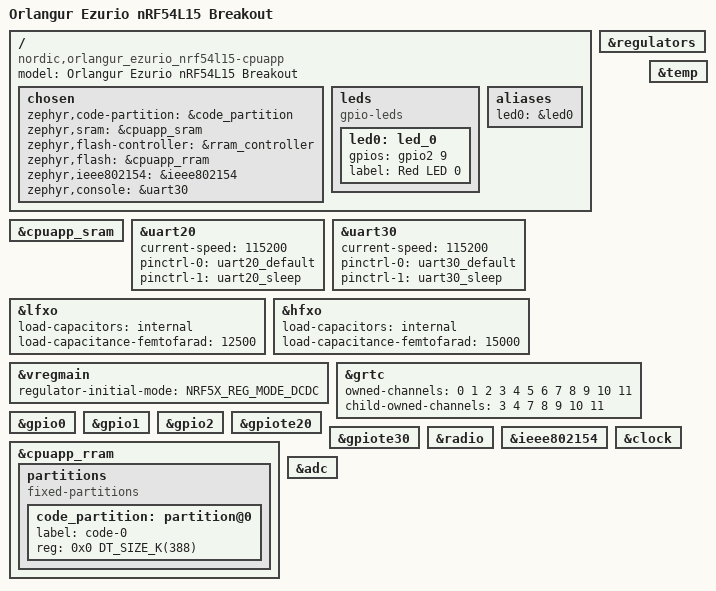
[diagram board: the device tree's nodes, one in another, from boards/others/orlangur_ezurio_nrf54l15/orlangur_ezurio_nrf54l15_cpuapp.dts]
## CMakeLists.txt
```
# SPDX-License-Identifier: Apache-2.0

cmake_minimum_required(VERSION 3.20.0)

find_package(Zephyr REQUIRED HINTS $ENV{ZEPHYR_BASE})
project(nrf54l15_breakout_test)

target_sources(app PRIVATE src/main.cpp)
target_link_libraries(app PRIVATE c stdc++ supc++)
target_compile_options(app PRIVATE -fmacro-backtrace-limit=0)
```

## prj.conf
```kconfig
#
# Copyright (c) 2020 Nordic Semiconductor ASA
#
# SPDX-License-Identifier: LicenseRef-Nordic-5-Clause
#
CONFIG_LIBGCC_RTLIB=y
CONFIG_PICOLIBC=y
CONFIG_CPP=y
CONFIG_STD_CPP2B=y
CONFIG_LLVM_USE_LLD=y
# CONFIG_LTO=y
# CONFIG_ISR_TABLES_LOCAL_DECLARATION=y

CONFIG_UART_INTERRUPT_DRIVEN=y
CONFIG_SERIAL=y
CONFIG_GPIO=y
# CONFIG_PWM=y
# CONFIG_ADC=y

CONFIG_REBOOT=y
CONFIG_RAM_POWER_DOWN_LIBRARY=y
CONFIG_SETTINGS=y
CONFIG_REGULATOR=y

CONFIG_CONSOLE=y
CONFIG_UART_CONSOLE=y

CONFIG_LOG=y
CONFIG_LOG_MAX_LEVEL=4
# CONFIG_LOG_BACKEND_RTT=y
# CONFIG_USE_SEGGER_RTT=y
CONFIG_PRINTK=y
```

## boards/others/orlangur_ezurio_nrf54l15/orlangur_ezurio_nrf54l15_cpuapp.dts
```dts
/*
 * Copyright (c) 2024 Nordic Semiconductor ASA
 *
 * SPDX-License-Identifier: Apache-2.0
 */

/dts-v1/;

#include <nordic/nrf54l15_cpuapp.dtsi>
#include "pinctrl.dtsi"

/ {
	compatible = "nordic,orlangur_ezurio_nrf54l15-cpuapp";
	model = "Orlangur Ezurio nRF54L15 Breakout";

	chosen {
		zephyr,code-partition = &code_partition;
		zephyr,sram = &cpuapp_sram;
		zephyr,flash-controller = &rram_controller;
		zephyr,flash = &cpuapp_rram;
		zephyr,ieee802154 = &ieee802154;
		zephyr,console = &uart30;
	};

	leds {
		compatible = "gpio-leds";
		led0: led_0 {
			gpios = <&gpio2 9 GPIO_ACTIVE_HIGH>;
			label = "Red LED 0";
		};
	};

	aliases {
		led0 = &led0;
	};
};

&cpuapp_sram {
	status = "okay";
};

&uart20 {
	current-speed = <115200>;
	pinctrl-0 = <&uart20_default>;
	pinctrl-1 = <&uart20_sleep>;
	pinctrl-names = "default", "sleep";
};

&uart30 {
	status = "okay";
	current-speed = <115200>;
	pinctrl-0 = <&uart30_default>;
	pinctrl-1 = <&uart30_sleep>;
	pinctrl-names = "default", "sleep";
};

&lfxo {
	load-capacitors = "internal";
	load-capacitance-femtofarad = <12500>;
};

&hfxo {
	load-capacitors = "internal";
	load-capacitance-femtofarad = <15000>;
};

&regulators {
	status = "okay";
};

&vregmain {
	status = "okay";
	regulator-initial-mode = <NRF5X_REG_MODE_DCDC>;
};

&grtc {
	owned-channels = <0 1 2 3 4 5 6 7 8 9 10 11>;
	/* Channels 7-11 reserved for Zero Latency IRQs, 3-4 for FLPR */
	child-owned-channels = <3 4 7 8 9 10 11>;
	status = "okay";
};

&gpio0 {
	status = "okay";
};

&gpio1 {
	status = "okay";
};

&gpio2 {
	status = "okay";
};

&gpiote20 {
	status = "okay";
};

&gpiote30 {
	status = "okay";
};

&radio {
	status = "okay";
};

&ieee802154 {
	status = "okay";
};

&temp {
	status = "okay";
};

&clock {
	status = "okay";
};

&cpuapp_rram {
	status = "okay";
	partitions {
		compatible = "fixed-partitions";
		#address-cells = <1>;
		#size-cells = <1>;
		code_partition: partition@0 {
			label = "code-0";
			reg = <0x0 DT_SIZE_K(388)>;
		};
	};
};

&adc {
	status = "okay";
};
```

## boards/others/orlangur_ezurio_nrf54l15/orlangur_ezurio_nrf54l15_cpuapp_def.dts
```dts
/*
 * Copyright (c) 2024 Nordic Semiconductor ASA
 *
 * SPDX-License-Identifier: Apache-2.0
 */

/dts-v1/;
#include "orlangur_ezurio_nrf54l15_cpuapp.dts"
```

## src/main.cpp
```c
/*
 * Copyright (c) 2023, Meta
 *
 * SPDX-License-Identifier: Apache-2.0
 */

//#include <iostream>
#include <memory>

#include <zephyr/kernel.h>
#include <zephyr/drivers/gpio.h>
#include <zephyr/drivers/uart.h>

/* 1000 msec = 1 sec */
#define SLEEP_TIME_MS   1000

/* The devicetree node identifier for the "led0" alias. */
#define LED0_NODE DT_ALIAS(led0)

#define UART_DEVICE_NODE DT_CHOSEN(zephyr_console)
static const struct device *const uart_dev = DEVICE_DT_GET(UART_DEVICE_NODE);

/*
 * A build error on this line means your board is unsupported.
 * See the sample documentation for information on how to fix this.
 */
static const struct gpio_dt_spec led = GPIO_DT_SPEC_GET(LED0_NODE, gpios);

void print_uart(const char *buf)
{
	while(*buf)
		uart_poll_out(uart_dev, *buf++);
}

int main(void)
{
	int ret;
	bool led_state = true;

	 if (!gpio_is_ready_dt(&led)) {
	 	return 0;
	 }
	 ret = gpio_pin_configure_dt(&led, GPIO_OUTPUT_ACTIVE);
	 if (ret < 0) {
	 	return 0;
	 }

	while (1) {
		 ret = gpio_pin_toggle_dt(&led);
		 if (ret < 0) return 0;

		led_state = !led_state;
		printk("LED: %s\r\n", led_state ? "ON" : "OFF");
		//if (led_state)
		//	print_uart("LED state: ON\r\n");
		//else
		//	print_uart("LED state: OFF\r\n");
		k_msleep(SLEEP_TIME_MS);
	}

	//std::unique_ptr<int> ptr;
	//std::shared_ptr<char> ptr2;
	//std::cout << "Hello, C++ world! " << CONFIG_BOARD << std::endl;
	//return (int)ptr.get();
	return 0;
}
```
